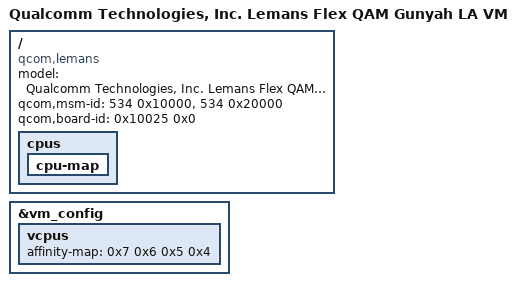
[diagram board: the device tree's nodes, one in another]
/dts-v1/;

#include "lemans-gunyah-vm-qam.dtsi"

/ {
	model = "Qualcomm Technologies, Inc. Lemans Flex QAM Gunyah LA VM";
	compatible = "qcom,lemans", "qcom,qam";
	qcom,msm-id = <534 0x10000>, <534 0x20000>;
	qcom,board-id = <0x10025 0x0>;

	cpus {
		/delete-node/ cpu@10000;
		/delete-node/ cpu@10100;
		/delete-node/ cpu@10200;
		/delete-node/ cpu@10300;

		cpu-map {
			/delete-node/ cluster1;
		};
	};
};

&vm_config {
	vcpus {
		affinity-map = <0x7 0x6 0x5 0x4>;
	};
};
